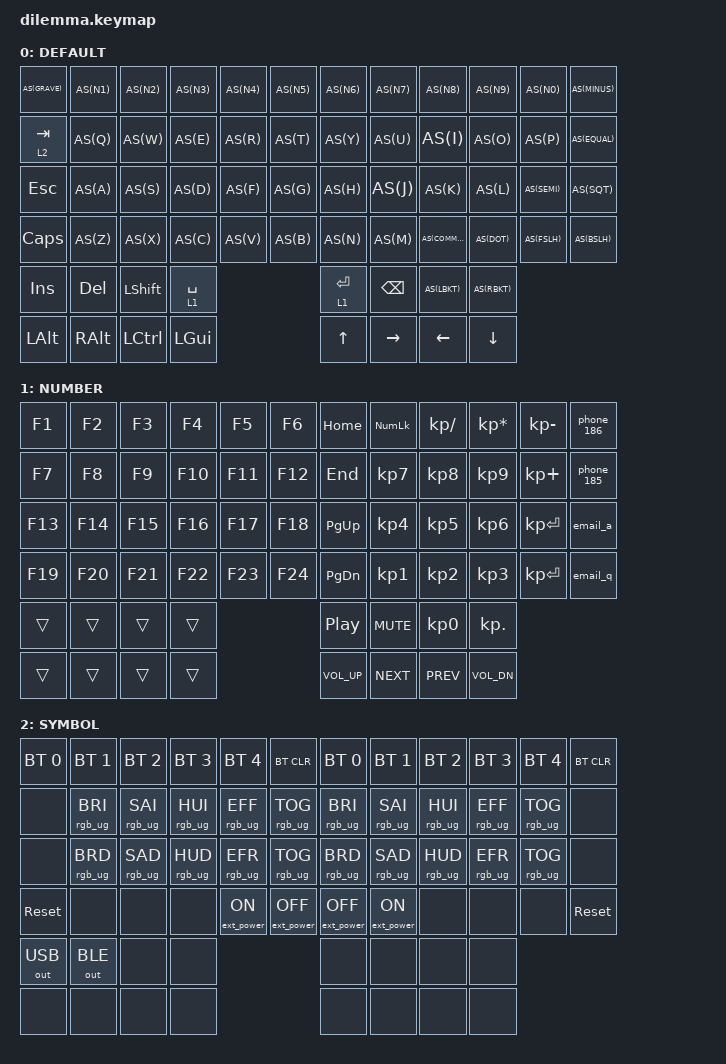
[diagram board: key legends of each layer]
#include <behaviors.dtsi>
#include <dt-bindings/zmk/bt.h>
#include <dt-bindings/zmk/ext_power.h>
#include <dt-bindings/zmk/keys.h>
#include <dt-bindings/zmk/outputs.h>
#include <dt-bindings/zmk/rgb.h>

#define DEFAULT 0
#define NUMBER  1
#define SYMBOL  2
#define HOTKEY  3

#define AS(keycode) &as LS(keycode) keycode

/ {
    behaviors {
        td0: tap_dance_0 {
            compatible = "zmk,behavior-tap-dance";
            label = "TAP_DANCE_0";
            #binding-cells = <0>;
            tapping-term-ms = <200>;
            bindings =
                <&kp ESC>,
                <&kp TAB>;
        };
    };

    behaviors {
        as: auto_shift {
            compatible = "zmk,behavior-hold-tap";
            label = "AUTO_SHIFT";
            #binding-cells = <2>;
            tapping-term-ms = <300>;
            quick-tap-ms = <0>;
            flavor = "tap-preferred";
            bindings =
                <&kp>,
                <&kp>;
        };
        modcp: mod_copy {
            compatible = "zmk,behavior-mod-morph";
            label = "MOD_COPY";
            #binding-cells = <0>;
            bindings =
                <&as LS(C) C>,
                <&kp C>;

            mods = <(LGUI | RGUI)>;
        };
    };

    macros {
        phone_186: phone_186 {
            // 18600042000

            compatible = "zmk,behavior-macro";
            #binding-cells = <0>;
            bindings = <&macro_tap &kp N1 &kp N8 &kp N6 &kp N0 &kp N0 &kp N0 &kp N4 &kp N2 &kp N0 &kp N0 &kp N0>;
        };
        phone_185: phone_185 {
            // 18515879420

            compatible = "zmk,behavior-macro";
            #binding-cells = <0>;
            bindings = <&macro_tap &kp N1 &kp N8 &kp N5 &kp N1 &kp N5 &kp N8 &kp N7 &kp N9 &kp N4 &kp N2 &kp N0>;
        }; 
        email_q: email_q {
            // 120469@qq.com

            compatible = "zmk,behavior-macro";
            #binding-cells = <0>;
            bindings = <&macro_tap &kp N1 &kp N2 &kp N0 &kp N4 &kp N6 &kp N9 &kp AT &kp Q &kp Q &kp DOT &kp C &kp O &kp M>;
        };
        email_a: email_a {
            // qinxue@icloud.com

            compatible = "zmk,behavior-macro";
            #binding-cells = <0>;
            bindings = <&macro_tap &kp Q &kp I &kp N &kp X &kp U &kp E &kp AT &kp I &kp C &kp L &kp O &kp U &kp D &kp DOT &kp C &kp O &kp M>;
        };
    };

    keymap {
        compatible = "zmk,keymap";

        default_layer {
            label = "DEFAULT";
            bindings = <
                AS(GRAVE)   AS(N1)   AS(N2)    AS(N3)  AS(N4)  AS(N5)         AS(N6)      AS(N7)    AS(N8)    AS(N9)   AS(N0)   AS(MINUS)
                &lt 2 TAB   AS(Q)    AS(W)     AS(E)   AS(R)   AS(T)          AS(Y)       AS(U)     AS(I)     AS(O)    AS(P)    AS(EQUAL)
                &kp ESC     AS(A)    AS(S)     AS(D)   AS(F)   AS(G)          AS(H)       AS(J)     AS(K)     AS(L)    AS(SEMI) AS(SQT)
                &kp CAPS    AS(Z)    AS(X)     AS(C)   AS(V)   AS(B)          AS(N)       AS(M)     AS(COMMA) AS(DOT)  AS(FSLH) AS(BSLH)  
                &kp INS     &kp DEL  &kp LSHFT  &lt 1 SPACE                   &lt 1 ENTER &kp BSPC  AS(LBKT)  AS(RBKT)          
                &kp LALT    &kp RALT &kp LCTRL   &kp LGUI                     &kp UP    &kp RIGHT &kp LEFT    &kp DOWN
            >;
        };

        number_layer {
            label = "NUMBER";
            bindings = <
                &kp F1   &kp F2    &kp F3    &kp F4    &kp F5    &kp F6         &kp HOME    &kp KP_NUM    &kp KP_SLASH     &kp KP_MULTIPLY  &kp KP_MINUS    &phone_186
                &kp F7   &kp F8    &kp F9    &kp F10   &kp F11   &kp F12        &kp END     &kp KP_N7     &kp KP_N8        &kp KP_N9        &kp KP_PLUS     &phone_185
                &kp F13  &kp F14   &kp F15   &kp F16   &kp F17   &kp F18        &kp PG_UP   &kp KP_N4     &kp KP_N5        &kp KP_N6        &kp KP_ENTER    &email_a
                &kp F19  &kp F20   &kp F21   &kp F22   &kp F23   &kp F24        &kp PG_DN   &kp KP_N1     &kp KP_N2        &kp KP_N3        &kp KP_ENTER    &email_q
                &trans   &trans   &trans  &trans                                &kp C_PP    &kp C_MUTE    &kp KP_N0        &kp KP_DOT
                &trans   &trans   &trans  &trans                                &kp C_VOL_UP       &kp C_NEXT        &kp C_PREV            &kp C_VOL_DN
            >;
        };

        symbol_layer {
            label = "SYMBOL";
            bindings = <
                &bt BT_SEL 0     &bt BT_SEL 1     &bt BT_SEL 2     &bt BT_SEL 3      &bt BT_SEL 4          &bt BT_CLR         &bt BT_SEL 0       &bt BT_SEL 1     &bt BT_SEL 2     &bt BT_SEL 3     &bt BT_SEL 4       &bt BT_CLR
                &none            &rgb_ug RGB_BRI  &rgb_ug RGB_SAI  &rgb_ug RGB_HUI   &rgb_ug RGB_EFF       &rgb_ug RGB_TOG    &rgb_ug RGB_BRI    &rgb_ug RGB_SAI  &rgb_ug RGB_HUI  &rgb_ug RGB_EFF  &rgb_ug RGB_TOG    &none
                &none            &rgb_ug RGB_BRD  &rgb_ug RGB_SAD  &rgb_ug RGB_HUD   &rgb_ug RGB_EFR       &rgb_ug RGB_TOG    &rgb_ug RGB_BRD    &rgb_ug RGB_SAD  &rgb_ug RGB_HUD  &rgb_ug RGB_EFR  &rgb_ug RGB_TOG    &none
                &sys_reset       &none            &none            &none             &ext_power EP_ON      &ext_power EP_OFF  &ext_power EP_OFF  &ext_power EP_ON &none            &none            &none              &sys_reset
                                    &out OUT_USB  &out OUT_BLE     &none             &none                 &none              &none              &none            &none
                                    &none         &none            &none             &none                 &none              &none              &none            &none
            >;
        };
    };
};
